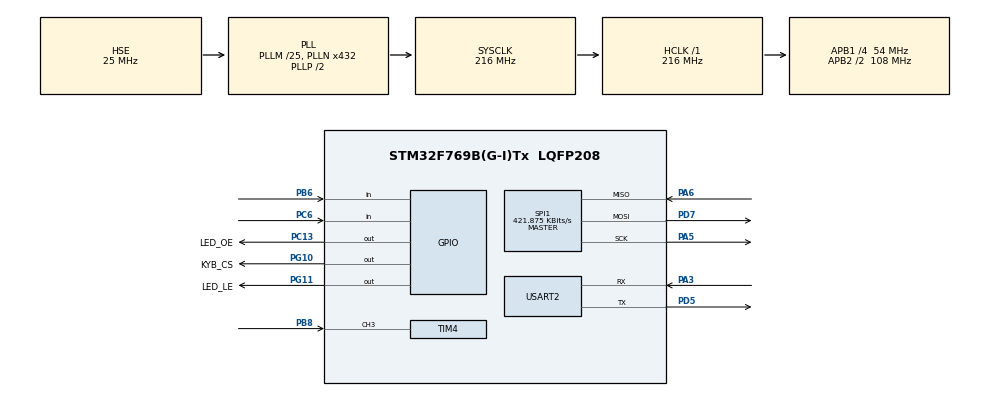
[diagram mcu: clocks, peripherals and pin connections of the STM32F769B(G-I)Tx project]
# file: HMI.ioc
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FREERTOS.Tasks01=defaultTask,24,128,StartDefaultTask,Default,NULL,Dynamic,NULL,NULL
FREERTOS.configUSE_NEWLIB_REENTRANT=1
Mcu.Family=STM32F7
Mcu.Name=STM32F769B(G-I)Tx
Mcu.Package=LQFP208
NVIC.PriorityGroup=NVIC_PRIORITYGROUP_4
NVIC.TIM2_IRQn=true\:15\:0\:false\:false\:true\:false\:false\:true\:true
NVIC.TIM4_IRQn=true\:5\:0\:false\:false\:true\:true\:true\:true\:true
NVIC.TimeBase=TIM2_IRQn
NVIC.TimeBaseIP=TIM2
NVIC.USART2_IRQn=true\:5\:0\:false\:true\:true\:1\:true\:true\:true\:true
PA3.Mode=Asynchronous
PA3.Signal=USART2_RX
PA5.Mode=Full_Duplex_Master
PA5.Signal=SPI1_SCK
PA6.Mode=Full_Duplex_Master
PA6.Signal=SPI1_MISO
PB6.Signal=GPIO_Input
PB8.Signal=S_TIM4_CH3
PC13.GPIO_Label=LED_OE
PC13.Signal=GPIO_Output
PC6.Signal=GPIO_Input
PD5.Mode=Asynchronous
PD5.Signal=USART2_TX
PD7.Mode=Full_Duplex_Master
PD7.Signal=SPI1_MOSI
PG10.GPIO_Label=KYB_CS
PG10.Signal=GPIO_Output
PG11.GPIO_Label=LED_LE
PG11.Signal=GPIO_Output
PH0/OSC_IN.Mode=HSE-External-Oscillator
PH0/OSC_IN.Signal=RCC_OSC_IN
PH1/OSC_OUT.Mode=HSE-External-Oscillator
PH1/OSC_OUT.Signal=RCC_OSC_OUT
ProjectManager.HeapSize=0x200
ProjectManager.StackSize=0x400
ProjectManager.TargetToolchain=STM32CubeIDE
RCC.AHBFreq_Value=216000000
RCC.APB1CLKDivider=RCC_HCLK_DIV4
RCC.APB1Freq_Value=54000000
RCC.APB1TimFreq_Value=108000000
RCC.APB2CLKDivider=RCC_HCLK_DIV2
RCC.APB2Freq_Value=108000000
RCC.APB2TimFreq_Value=216000000
RCC.CortexFreq_Value=216000000
RCC.HCLKFreq_Value=216000000
RCC.HSE_VALUE=25000000
RCC.HSI_VALUE=16000000
RCC.LSE_VALUE=32768
RCC.PLLM=25
RCC.PLLN=432
RCC.PLLSourceVirtual=RCC_PLLSOURCE_HSE
RCC.SYSCLKFreq_VALUE=216000000
RCC.SYSCLKSource=RCC_SYSCLKSOURCE_PLLCLK
RCC.USBFreq_Value=216000000
RCC.VCOOutputFreq_Value=432000000
SH.S_TIM4_CH3.0=TIM4_CH3,Input_Capture3_from_TI3
SPI1.BaudRatePrescaler=SPI_BAUDRATEPRESCALER_256
SPI1.CalculateBaudRate=421.875 KBits/s
SPI1.DataSize=SPI_DATASIZE_8BIT
SPI1.Direction=SPI_DIRECTION_2LINES
SPI1.Mode=SPI_MODE_MASTER
SPI1.VirtualType=VM_MASTER
TIM4.AutoReloadPreload=TIM_AUTORELOAD_PRELOAD_ENABLE
TIM4.Channel-Input_Capture3_from_TI3=TIM_CHANNEL_3
TIM4.ICPolarity_CH3=TIM_INPUTCHANNELPOLARITY_FALLING
TIM4.Period=65534
TIM4.Prescaler=0
USART2.VirtualMode-Asynchronous=VM_ASYNC
VP_FREERTOS_VS_CMSIS_V2.Mode=CMSIS_V2
VP_SYS_VS_tim2.Mode=TIM2
board=custom

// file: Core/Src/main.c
/* USER CODE BEGIN Header */
/**
  ******************************************************************************
  * @file           : main.c
  * @brief          : Main program body
  ******************************************************************************
  * @attention
  *
  * Copyright (c) 2022 STMicroelectronics.
  * All rights reserved.
  *
  * This software is licensed under terms that can be found in the LICENSE file
  * in the root directory of this software component.
  * If no LICENSE file comes with this software, it is provided AS-IS.
  *
  ******************************************************************************
  */
/* USER CODE END Header */
#include "main.h"
#include "cmsis_os.h"

/* USER CODE BEGIN Includes */
#include "application.h"
/* USER CODE END Includes */

SPI_HandleTypeDef hspi1;

TIM_HandleTypeDef htim4;

UART_HandleTypeDef huart2;

/* Definitions for defaultTask */
osThreadId_t defaultTaskHandle;
const osThreadAttr_t defaultTask_attributes = {
  .name = "defaultTask",
  .stack_size = 128 * 4,
  .priority = (osPriority_t) osPriorityNormal,
};

void SystemClock_Config(void);
static void MX_GPIO_Init(void);
static void MX_USART2_UART_Init(void);
static void MX_SPI1_Init(void);
static void MX_TIM4_Init(void);
void StartDefaultTask(void *argument);

static void MX_NVIC_Init(void);

int main(void)
{

  /* MCU Configuration--------------------------------------------------------*/

  /* Reset of all peripherals, Initializes the Flash interface and the Systick. */
  HAL_Init();

  /* Configure the system clock */
  SystemClock_Config();

  /* Initialize all configured peripherals */
  MX_GPIO_Init();
  MX_USART2_UART_Init();
  MX_SPI1_Init();
  MX_TIM4_Init();

  /* Initialize interrupts */
  MX_NVIC_Init();
  /* USER CODE BEGIN 2 */
 // HAL_UART_Transmit( &huart2, "WelCome", 7, 100);

  /* USER CODE END 2 */

  /* Init scheduler */
  osKernelInitialize();

  /* Create the thread(s) */
  /* creation of defaultTask */
  defaultTaskHandle = osThreadNew(StartDefaultTask, NULL, &defaultTask_attributes);

  /* USER CODE BEGIN RTOS_THREADS */

  HAL_TIM_IC_Start_IT(&htim4, TIM_CHANNEL_3);

  application();
  /* add threads, ... */
  /* USER CODE END RTOS_THREADS */

  /* Start scheduler */
  osKernelStart();

  /* We should never get here as control is now taken by the scheduler */
  /* Infinite loop */
  while (1)
  {

  }
}

void SystemClock_Config(void)
{
  RCC_OscInitTypeDef RCC_OscInitStruct = {0};
  RCC_ClkInitTypeDef RCC_ClkInitStruct = {0};

  /** Configure the main internal regulator output voltage
  */
  __HAL_RCC_PWR_CLK_ENABLE();
  __HAL_PWR_VOLTAGESCALING_CONFIG(PWR_REGULATOR_VOLTAGE_SCALE1);

  /** Initializes the RCC Oscillators according to the specified parameters
  * in the RCC_OscInitTypeDef structure.
  */
  RCC_OscInitStruct.OscillatorType = RCC_OSCILLATORTYPE_HSE;
  RCC_OscInitStruct.HSEState = RCC_HSE_ON;
  RCC_OscInitStruct.PLL.PLLState = RCC_PLL_ON;
  RCC_OscInitStruct.PLL.PLLSource = RCC_PLLSOURCE_HSE;
  RCC_OscInitStruct.PLL.PLLM = 25;
  RCC_OscInitStruct.PLL.PLLN = 432;
  RCC_OscInitStruct.PLL.PLLP = RCC_PLLP_DIV2;
  RCC_OscInitStruct.PLL.PLLQ = 2;
  RCC_OscInitStruct.PLL.PLLR = 2;
  if (HAL_RCC_OscConfig(&RCC_OscInitStruct) != HAL_OK)
  {
    Error_Handler();
  }

  /** Activate the Over-Drive mode
  */
  if (HAL_PWREx_EnableOverDrive() != HAL_OK)
  {
    Error_Handler();
  }

  /** Initializes the CPU, AHB and APB buses clocks
  */
  RCC_ClkInitStruct.ClockType = RCC_CLOCKTYPE_HCLK|RCC_CLOCKTYPE_SYSCLK
                              |RCC_CLOCKTYPE_PCLK1|RCC_CLOCKTYPE_PCLK2;
  RCC_ClkInitStruct.SYSCLKSource = RCC_SYSCLKSOURCE_PLLCLK;
  RCC_ClkInitStruct.AHBCLKDivider = RCC_SYSCLK_DIV1;
  RCC_ClkInitStruct.APB1CLKDivider = RCC_HCLK_DIV4;
  RCC_ClkInitStruct.APB2CLKDivider = RCC_HCLK_DIV2;

  if (HAL_RCC_ClockConfig(&RCC_ClkInitStruct, FLASH_LATENCY_7) != HAL_OK)
  {
    Error_Handler();
  }
}

/**
  * @brief NVIC Configuration.
  * @retval None
  */
static void MX_NVIC_Init(void)
{
  /* USART2_IRQn interrupt configuration */
  HAL_NVIC_SetPriority(USART2_IRQn, 5, 0);
  HAL_NVIC_EnableIRQ(USART2_IRQn);
}

static void MX_SPI1_Init(void)
{

  /* SPI1 parameter configuration*/
  hspi1.Instance = SPI1;
  hspi1.Init.Mode = SPI_MODE_MASTER;
  hspi1.Init.Direction = SPI_DIRECTION_2LINES;
  hspi1.Init.DataSize = SPI_DATASIZE_8BIT;
  hspi1.Init.CLKPolarity = SPI_POLARITY_LOW;
  hspi1.Init.CLKPhase = SPI_PHASE_1EDGE;
  hspi1.Init.NSS = SPI_NSS_SOFT;
  hspi1.Init.BaudRatePrescaler = SPI_BAUDRATEPRESCALER_256;
  hspi1.Init.FirstBit = SPI_FIRSTBIT_MSB;
  hspi1.Init.TIMode = SPI_TIMODE_DISABLE;
  hspi1.Init.CRCCalculation = SPI_CRCCALCULATION_DISABLE;
  hspi1.Init.CRCPolynomial = 7;
  hspi1.Init.CRCLength = SPI_CRC_LENGTH_DATASIZE;
  hspi1.Init.NSSPMode = SPI_NSS_PULSE_ENABLE;
  if (HAL_SPI_Init(&hspi1) != HAL_OK)
  {
    Error_Handler();
  }

}

static void MX_TIM4_Init(void)
{

  TIM_MasterConfigTypeDef sMasterConfig = {0};
  TIM_IC_InitTypeDef sConfigIC = {0};

  htim4.Instance = TIM4;
  htim4.Init.Prescaler = 0;
  htim4.Init.CounterMode = TIM_COUNTERMODE_UP;
  htim4.Init.Period = 65534;
  htim4.Init.ClockDivision = TIM_CLOCKDIVISION_DIV1;
  htim4.Init.AutoReloadPreload = TIM_AUTORELOAD_PRELOAD_ENABLE;
  if (HAL_TIM_IC_Init(&htim4) != HAL_OK)
  {
    Error_Handler();
  }
  sMasterConfig.MasterOutputTrigger = TIM_TRGO_RESET;
  sMasterConfig.MasterSlaveMode = TIM_MASTERSLAVEMODE_DISABLE;
  if (HAL_TIMEx_MasterConfigSynchronization(&htim4, &sMasterConfig) != HAL_OK)
  {
    Error_Handler();
  }
  sConfigIC.ICPolarity = TIM_INPUTCHANNELPOLARITY_FALLING;
  sConfigIC.ICSelection = TIM_ICSELECTION_DIRECTTI;
  sConfigIC.ICPrescaler = TIM_ICPSC_DIV1;
  sConfigIC.ICFilter = 0;
  if (HAL_TIM_IC_ConfigChannel(&htim4, &sConfigIC, TIM_CHANNEL_3) != HAL_OK)
  {
    Error_Handler();
  }

}

static void MX_USART2_UART_Init(void)
{

  huart2.Instance = USART2;
  huart2.Init.BaudRate = 115200;
  huart2.Init.WordLength = UART_WORDLENGTH_8B;
  huart2.Init.StopBits = UART_STOPBITS_1;
  huart2.Init.Parity = UART_PARITY_NONE;
  huart2.Init.Mode = UART_MODE_TX_RX;
  huart2.Init.HwFlowCtl = UART_HWCONTROL_NONE;
  huart2.Init.OverSampling = UART_OVERSAMPLING_16;
  huart2.Init.OneBitSampling = UART_ONE_BIT_SAMPLE_DISABLE;
  huart2.AdvancedInit.AdvFeatureInit = UART_ADVFEATURE_NO_INIT;
  if (HAL_UART_Init(&huart2) != HAL_OK)
  {
    Error_Handler();
  }

}

static void MX_GPIO_Init(void)
{
  GPIO_InitTypeDef GPIO_InitStruct = {0};

  /* GPIO Ports Clock Enable */
  __HAL_RCC_GPIOC_CLK_ENABLE();
  __HAL_RCC_GPIOH_CLK_ENABLE();
  __HAL_RCC_GPIOA_CLK_ENABLE();
  __HAL_RCC_GPIOD_CLK_ENABLE();
  __HAL_RCC_GPIOG_CLK_ENABLE();
  __HAL_RCC_GPIOB_CLK_ENABLE();

  /*Configure GPIO pin Output Level */
  HAL_GPIO_WritePin(LED_OE_GPIO_Port, LED_OE_Pin, GPIO_PIN_RESET);

  /*Configure GPIO pin Output Level */
  HAL_GPIO_WritePin(GPIOG, KYB_CS_Pin|LED_LE_Pin, GPIO_PIN_RESET);

  /*Configure GPIO pin : LED_OE_Pin */
  GPIO_InitStruct.Pin = LED_OE_Pin;
  GPIO_InitStruct.Mode = GPIO_MODE_OUTPUT_PP;
  GPIO_InitStruct.Pull = GPIO_NOPULL;
  GPIO_InitStruct.Speed = GPIO_SPEED_FREQ_LOW;
  HAL_GPIO_Init(LED_OE_GPIO_Port, &GPIO_InitStruct);

  /*Configure GPIO pin : PC6 */
  GPIO_InitStruct.Pin = GPIO_PIN_6;
  GPIO_InitStruct.Mode = GPIO_MODE_INPUT;
  GPIO_InitStruct.Pull = GPIO_NOPULL;
  HAL_GPIO_Init(GPIOC, &GPIO_InitStruct);

  /*Configure GPIO pins : KYB_CS_Pin LED_LE_Pin */
  GPIO_InitStruct.Pin = KYB_CS_Pin|LED_LE_Pin;
  GPIO_InitStruct.Mode = GPIO_MODE_OUTPUT_PP;
  GPIO_InitStruct.Pull = GPIO_NOPULL;
  GPIO_InitStruct.Speed = GPIO_SPEED_FREQ_LOW;
  HAL_GPIO_Init(GPIOG, &GPIO_InitStruct);

  /*Configure GPIO pin : PB6 */
  GPIO_InitStruct.Pin = GPIO_PIN_6;
  GPIO_InitStruct.Mode = GPIO_MODE_INPUT;
  GPIO_InitStruct.Pull = GPIO_NOPULL;
  HAL_GPIO_Init(GPIOB, &GPIO_InitStruct);

}

void StartDefaultTask(void *argument)
{
  /* USER CODE BEGIN 5 */

  /* Infinite loop */
  for(;;)
  {
//	  	  HAL_SPI_Transmit ( &hspi1, (uint8_t*) &leds, 18, 0xFFFF );
//	  	  HAL_GPIO_WritePin(GPIOG, GPIO_PIN_11 , GPIO_PIN_SET);  //LE
//	      osDelay ( 1 );
//	      HAL_GPIO_WritePin(GPIOG, GPIO_PIN_11 , GPIO_PIN_RESET);  //LE;
//	      osDelay ( 1 );
//	      HAL_GPIO_WritePin(GPIOC, GPIO_PIN_13 , GPIO_PIN_RESET);  //LE;
//
//	      leds.var1=leds.var1<<1;
//	      leds.var2 = leds.var2>>1;
    osDelay(1);
  }
  /* USER CODE END 5 */
}

void HAL_TIM_PeriodElapsedCallback(TIM_HandleTypeDef *htim)
{
  if (htim->Instance == TIM2) {
    HAL_IncTick();
  }
}

void Error_Handler(void)
{
  __disable_irq();
  while (1)
  {
  }
}
